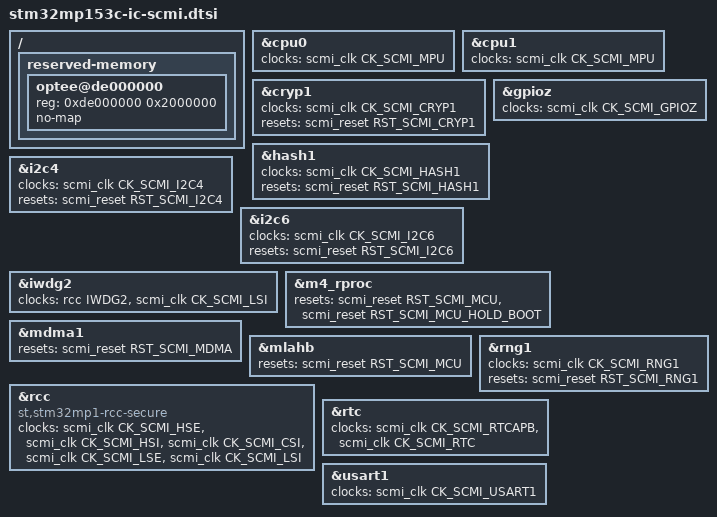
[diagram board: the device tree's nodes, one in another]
// SPDX-License-Identifier: (GPL-2.0+ OR BSD-3-Clause)

/*
FHG IML: This dtsi file is a copy of stm32mp157c-dk2-scmi.dtsi with the dsi node removed

This file is necessary to change all the clocks which are initially set in stm32mp151.dtsi to
either &rcc or &clk_hse, &clk_hsi, ...  to &scmi_clk clocks. The scmi_clk clocks need to be
used (at least where &clk_... has been used before) because the stm32mp15-scmi.dtsi include
removes the &clk_... nodes.
*/

/*
 * Copyright (C) STMicroelectronics 2022 - All Rights Reserved
 * Author: Alexandre Torgue <alexandre.torgue@foss.st.com> for STMicroelectronics.
 */

#include "stm32mp15-scmi.dtsi"

/ {
	reserved-memory {
		optee@de000000 {
			reg = <0xde000000 0x2000000>;
			no-map;
		};
	};
};

&cpu0 {
	clocks = <&scmi_clk CK_SCMI_MPU>;
};

&cpu1 {
	clocks = <&scmi_clk CK_SCMI_MPU>;
};

&cryp1 {
	clocks = <&scmi_clk CK_SCMI_CRYP1>;
	resets = <&scmi_reset RST_SCMI_CRYP1>;
};

&gpioz {
	clocks = <&scmi_clk CK_SCMI_GPIOZ>;
};

&hash1 {
	clocks = <&scmi_clk CK_SCMI_HASH1>;
	resets = <&scmi_reset RST_SCMI_HASH1>;
};

&i2c4 {
	clocks = <&scmi_clk CK_SCMI_I2C4>;
	resets = <&scmi_reset RST_SCMI_I2C4>;
};

&i2c6 {
	clocks = <&scmi_clk CK_SCMI_I2C6>;
	resets = <&scmi_reset RST_SCMI_I2C6>;
};

&iwdg2 {
	clocks = <&rcc IWDG2>, <&scmi_clk CK_SCMI_LSI>;
};

&m4_rproc {
	resets = <&scmi_reset RST_SCMI_MCU>,
		 <&scmi_reset RST_SCMI_MCU_HOLD_BOOT>;
	reset-names = "mcu_rst", "hold_boot";
	/delete-property/ st,syscfg-holdboot;
};

&mdma1 {
	resets = <&scmi_reset RST_SCMI_MDMA>;
};

&mlahb {
	resets = <&scmi_reset RST_SCMI_MCU>;
};

&rcc {
	compatible = "st,stm32mp1-rcc-secure", "syscon";
	clock-names = "hse", "hsi", "csi", "lse", "lsi";
	clocks = <&scmi_clk CK_SCMI_HSE>,
		 <&scmi_clk CK_SCMI_HSI>,
		 <&scmi_clk CK_SCMI_CSI>,
		 <&scmi_clk CK_SCMI_LSE>,
		 <&scmi_clk CK_SCMI_LSI>;
};

&rng1 {
	clocks = <&scmi_clk CK_SCMI_RNG1>;
	resets = <&scmi_reset RST_SCMI_RNG1>;
};

&rtc {
	clocks = <&scmi_clk CK_SCMI_RTCAPB>, <&scmi_clk CK_SCMI_RTC>;
};

&usart1 {
	clocks = <&scmi_clk CK_SCMI_USART1>;
};
